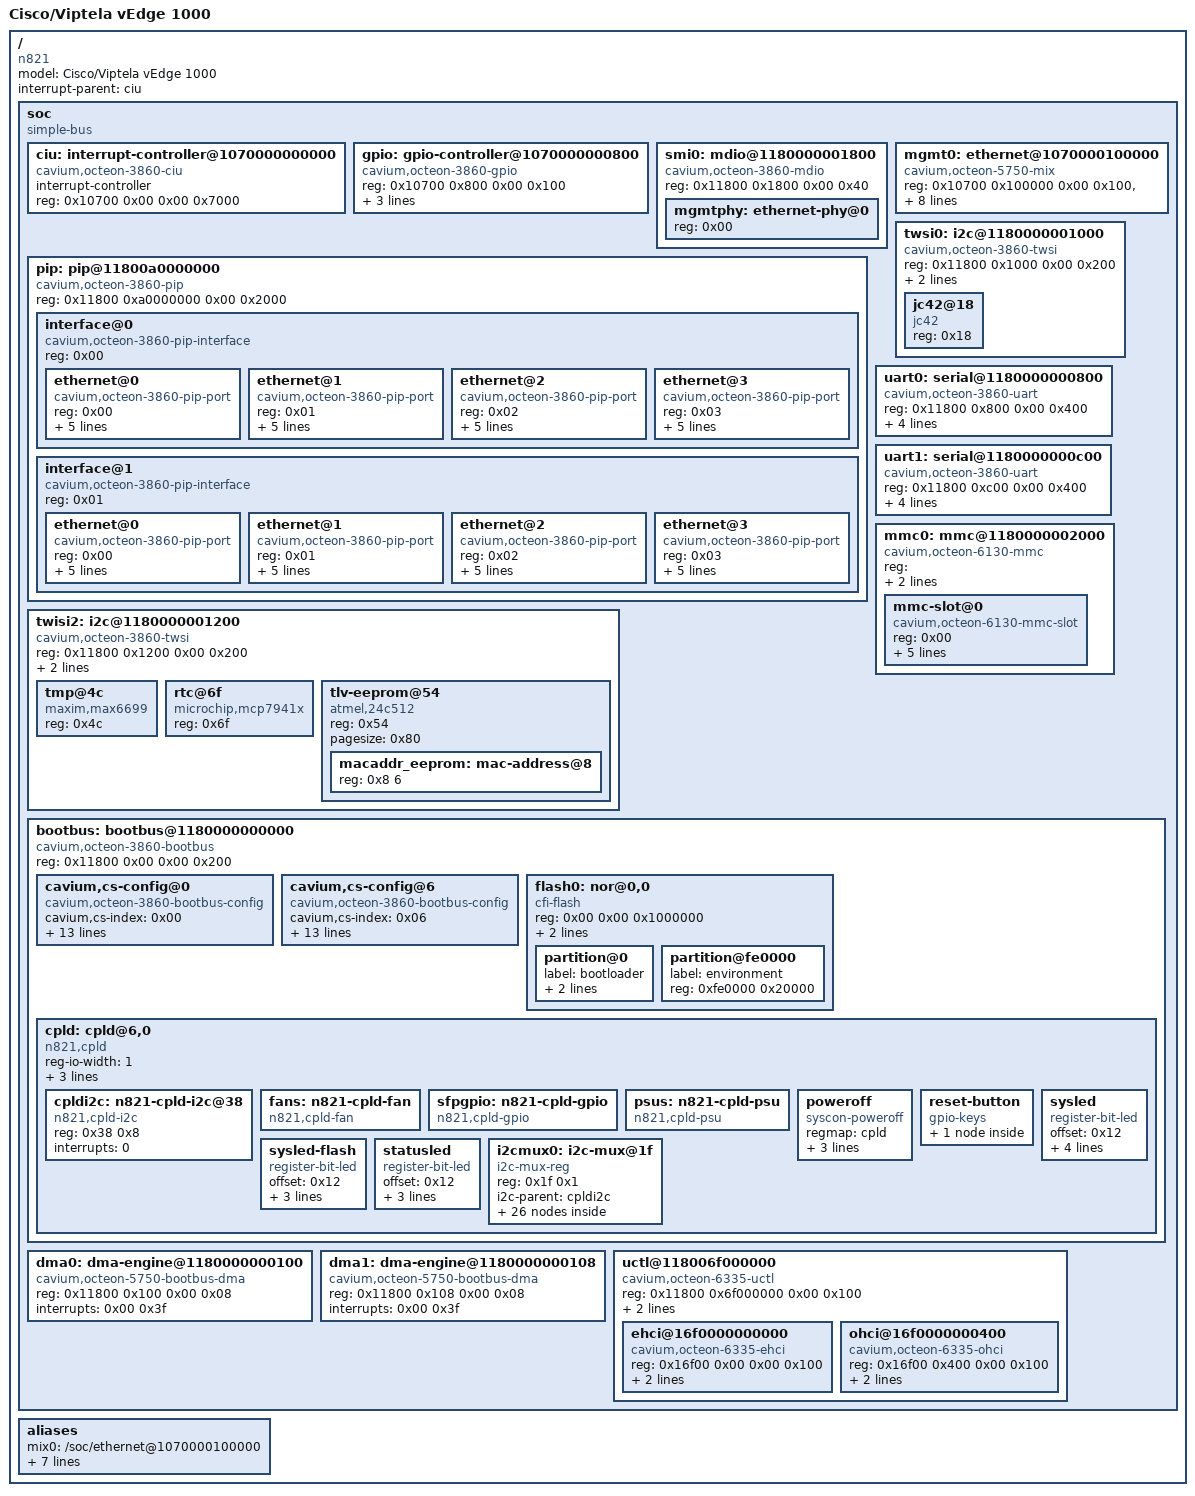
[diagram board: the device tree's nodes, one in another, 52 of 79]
/dts-v1/;

#include <dt-bindings/gpio/gpio.h>
#include <dt-bindings/input/input.h>
#include <dt-bindings/interrupt-controller/irq.h>

/ {
        model = "Cisco/Viptela vEdge 1000";
        compatible = "n821";
        #address-cells = <2>;
        #size-cells = <2>;
        interrupt-parent = <&ciu>;

        soc {
                compatible = "simple-bus";
                #address-cells = <2>;
                #size-cells = <2>;
                ranges; /* Direct mapping */

                ciu: interrupt-controller@1070000000000 {
                        compatible = "cavium,octeon-3860-ciu";
                        interrupt-controller;
                        #interrupt-cells = <2>;
                        reg = <0x10700 0x00 0x00 0x7000>;
                };

                gpio: gpio-controller@1070000000800 {
                        #gpio-cells = <2>;
                        compatible = "cavium,octeon-3860-gpio";
                        reg = <0x10700 0x800 0x00 0x100>;
                        gpio-controller;
                        interrupt-controller;
                        #interrupt-cells = <2>;
                        interrupts = <0x00 0x10>;
                };

                smi0: mdio@1180000001800 {
                        compatible = "cavium,octeon-3860-mdio";
                        #address-cells = <1>;
                        #size-cells = <0>;
                        reg = <0x11800 0x1800 0x00 0x40>;

                        mgmtphy: ethernet-phy@0 {
                                reg = <0x00>;
                        };
                };

                mgmt0: ethernet@1070000100000 {
                        compatible = "cavium,octeon-5750-mix";
                        reg = <0x10700 0x100000 0x00 0x100>,
                              <0x11800 0xe0000000 0x00 0x300>,
                              <0x11800 0xe0000400 0x00 0x400>,
                              <0x11800 0xe0002000 0x00 0x08>;
                        cell-index = <0x00>;
                        interrupts = <0x00 0x3e 0x01 0x2e>;
                        nvmem-cells = <&macaddr_eeprom>;
                        nvmem-cell-names = "mac-address";
                        phy-handle = <&mgmtphy>;
                };

                pip: pip@11800a0000000 {
                        compatible = "cavium,octeon-3860-pip";
                        #address-cells = <1>;
                        #size-cells = <0>;
                        reg = <0x11800 0xa0000000 0x00 0x2000>;

                        interface@0 {
                                compatible = "cavium,octeon-3860-pip-interface";
                                #address-cells = <1>;
                                #size-cells = <0>;
                                reg = <0x00>;

                                ethernet@0 {
                                        compatible = "cavium,octeon-3860-pip-port";
                                        reg = <0x00>;
                                        nvmem-cells = <&macaddr_eeprom>;
                                        nvmem-cell-names = "mac-address";
                                        mac-address-increment = <(3)>;
                                        label = "lan2";
                                        phy-handle = <&ge0_2_phy>;
                                };

                                ethernet@1 {
                                        compatible = "cavium,octeon-3860-pip-port";
                                        reg = <0x01>;
                                        nvmem-cells = <&macaddr_eeprom>;
                                        nvmem-cell-names = "mac-address";
                                        mac-address-increment = <(4)>;
                                        label = "lan3";
                                        phy-handle = <&ge0_3_phy>;
                                };

                                ethernet@2 {
                                        compatible = "cavium,octeon-3860-pip-port";
                                        reg = <0x02>;
                                        nvmem-cells = <&macaddr_eeprom>;
                                        nvmem-cell-names = "mac-address";
                                        mac-address-increment = <(1)>;
                                        label = "lan0";
                                        cavium,sgmii-mac-1000x-mode;
                                };

                                ethernet@3 {
                                        compatible = "cavium,octeon-3860-pip-port";
                                        reg = <0x03>;
                                        nvmem-cells = <&macaddr_eeprom>;
                                        nvmem-cell-names = "mac-address";
                                        mac-address-increment = <(2)>;
                                        label = "lan1";
                                        cavium,sgmii-mac-1000x-mode;
                                };
                        };

                        interface@1 {
                                compatible = "cavium,octeon-3860-pip-interface";
                                #address-cells = <1>;
                                #size-cells = <0>;
                                reg = <0x01>;

                                ethernet@0 {
                                        compatible = "cavium,octeon-3860-pip-port";
                                        reg = <0x00>;
                                        nvmem-cells = <&macaddr_eeprom>;
                                        nvmem-cell-names = "mac-address";
                                        mac-address-increment = <(7)>;
                                        label = "lan6";
                                        phy-handle = <&ge0_6_phy>;
                                };

                                ethernet@1 {
                                        compatible = "cavium,octeon-3860-pip-port";
                                        reg = <0x01>;
                                        nvmem-cells = <&macaddr_eeprom>;
                                        nvmem-cell-names = "mac-address";
                                        mac-address-increment = <(8)>;
                                        label = "lan7";
                                        phy-handle = <&ge0_7_phy>;
                                };

                                ethernet@2 {
                                        compatible = "cavium,octeon-3860-pip-port";
                                        reg = <0x02>;
                                        nvmem-cells = <&macaddr_eeprom>;
                                        nvmem-cell-names = "mac-address";
                                        mac-address-increment = <(5)>;
                                        label = "lan4";
                                        phy-handle = <&ge0_4_phy>;
                                };

                                ethernet@3 {
                                        compatible = "cavium,octeon-3860-pip-port";
                                        reg = <0x03>;
                                        nvmem-cells = <&macaddr_eeprom>;
                                        nvmem-cell-names = "mac-address";
                                        mac-address-increment = <(6)>;
                                        label = "lan5";
                                        phy-handle = <&ge0_5_phy>;
                                };
                        };
                };

                twsi0: i2c@1180000001000 {
                        #address-cells = <1>;
                        #size-cells = <0>;
                        compatible = "cavium,octeon-3860-twsi";
                        reg = <0x11800 0x1000 0x00 0x200>;
                        interrupts = <0x00 0x2d>;
                        clock-frequency = <400000>;

                        jc42@18 {
                                compatible = "jc42";
                                reg = <0x18>;
                        };
                };

                twisi2: i2c@1180000001200 {
                        #address-cells = <1>;
                        #size-cells = <0>;
                        compatible = "cavium,octeon-3860-twsi";
                        reg = <0x11800 0x1200 0x00 0x200>;
                        interrupts = <0x00 0x3b>;
                        clock-frequency = <400000>;

                        tmp@4c {
                                compatible = "maxim,max6699";
                                reg = <0x4c>;
                        };

                        rtc@6f {
                                compatible = "microchip,mcp7941x";
                                reg = <0x6f>;
                        };

                        tlv-eeprom@54 {
                                compatible = "atmel,24c512";
                                reg = <0x54>;
                                pagesize = <0x80>;
                                #address-cells = <1>;
                                #size-cells = <1>;

                                macaddr_eeprom: mac-address@8 {
                                        reg = <0x8 6>;
                                };
                        };
                };

                uart0: serial@1180000000800 {
                        compatible = "cavium,octeon-3860-uart", "ns16550";
                        reg = <0x11800 0x800 0x00 0x400>;
                        reg-shift = <0x03>;
                        interrupts = <0x00 0x22>;
                        clock-frequency = <600000000>;
                        current-speed = <115200>;
                };

                uart1: serial@1180000000c00 {
                        compatible = "cavium,octeon-3860-uart", "ns16550";
                        reg = <0x11800 0xc00 0x00 0x400>;
                        reg-shift = <0x03>;
                        interrupts = <0x00 0x23>;
                        clock-frequency = <600000000>;
                        current-speed = <115200>;
                };

                mmc0: mmc@1180000002000 {
                        compatible = "cavium,octeon-6130-mmc";
                        reg = <0x11800 0x2000 0x00 0x100 0x11800 0x168 0x00 0x20>;
                        #address-cells = <1>;
                        #size-cells = <0>;
                        interrupts = <0x01 0x13 0x00 0x3f>;

                        mmc-slot@0 {
                                compatible = "cavium,octeon-6130-mmc-slot";
                                reg = <0x00>;
                                voltage-ranges = <0xce4 0xce4>;
                                max-frequency = <0x3197500>;
                                wp-gpios = <&gpio 0x02 0x00>;
                                cd-gpios = <&gpio 0x03 0x01>;
                                cavium,bus-max-width = <0x04>;
                        };
                };

                bootbus: bootbus@1180000000000 {
                        compatible = "cavium,octeon-3860-bootbus";
                        reg = <0x11800 0x00 0x00 0x200>;
                        #address-cells = <2>;
                        #size-cells = <1>;
                        ranges = <0 0 0x00 0x1ec00000 0x1400000>,
                                 <1 0 0x10000 0x20000000 0x00>,
                                 <2 0 0x10000 0x30000000 0x00>,
                                 <3 0 0x10000 0x40000000 0x00>,
                                 <4 0 0x10000 0x50000000 0x00>,
                                 <5 0 0x10000 0x60000000 0x00>,
                                 <6 0 0x00 0x1e000000 0x10000>,
                                 <7 0 0x10000 0x80000000 0x00>;

                        cavium,cs-config@0 {
                                compatible = "cavium,octeon-3860-bootbus-config";
                                cavium,cs-index = <0x00>;
                                cavium,t-adr = <0x0a>;
                                cavium,t-ce = <0x32>;
                                cavium,t-oe = <0x32>;
                                cavium,t-we = <0x23>;
                                cavium,t-rd-hld = <0x19>;
                                cavium,t-wr-hld = <0x23>;
                                cavium,t-pause = <0x00>;
                                cavium,t-wait = <0x12c>;
                                cavium,t-page = <0x19>;
                                cavium,t-rd-dly = <0x00>;
                                cavium,t-ale = <0x03>;
                                cavium,pages = <0x00>;
                                cavium,bus-width = <0x10>;
                        };

                        cavium,cs-config@6 {
                                compatible = "cavium,octeon-3860-bootbus-config";
                                cavium,cs-index = <0x06>;
                                cavium,t-adr = <0x0a>;
                                cavium,t-ce = <0x0a>;
                                cavium,t-oe = <0xa0>;
                                cavium,t-we = <0x64>;
                                cavium,t-rd-hld = <0x00>;
                                cavium,t-wr-hld = <0x00>;
                                cavium,t-pause = <0x32>;
                                cavium,t-wait = <0x12c>;
                                cavium,t-page = <0x12c>;
                                cavium,t-rd-dly = <0x0a>;
                                cavium,t-ale = <0x3f>;
                                cavium,pages = <0x00>;
                                cavium,bus-width = <0x08>;
                        };

                        flash0: nor@0,0 {
                                compatible = "cfi-flash";
                                reg = <0x00 0x00 0x1000000>;
                                /* not sure about these values */
                                bank-width = <2>;
                                device-width = <1>;

                                #address-cells = <1>;
                                #size-cells = <1>;

                                partition@0 {
                                        label = "bootloader";
                                        reg = <0x00 0x200000>;
                                        read-only;
                                };

                                partition@fe0000 {
                                        label = "environment";
                                        reg = <0xfe0000 0x20000>;
                                };
                        };

                        cpld: cpld@6,0 {
                                compatible = "n821,cpld", "syscon", "simple-mfd";
                                #address-cells = <1>;
                                #size-cells = <1>;
                                reg-io-width = <1>; // Syscon uses 4-byte accesses by default

                                reg = <0x06 0x00 0x28>;     // This is the regmap to be defined for syscon devices..
                                ranges = <0 0x06 0x0 0x50>; // .. and this is the addresses to map general subdevices on

                                interrupt-controller;
                                #interrupt-cells = <1>;
                                interrupts-extended = <&gpio 1 IRQ_TYPE_LEVEL_LOW>;

                                cpldi2c: n821-cpld-i2c@38 {
                                        compatible = "n821,cpld-i2c";
                                        reg = <0x38 0x8>;
                                        interrupts = <0>; // TODO: Verify correct IRQ
                                };

                                fans: n821-cpld-fan {
                                        compatible = "n821,cpld-fan";
                                };

                                sfpgpio: n821-cpld-gpio {
                                        compatible = "n821,cpld-gpio";
                                        #gpio-cells = <2>;
                                };

                                psus: n821-cpld-psu {
                                        compatible = "n821,cpld-psu";
                                };

                                poweroff {
                                        compatible = "syscon-poweroff";
                                        regmap = <&cpld>;
                                        offset = <0x5>;
                                        value = <0>;
                                        mask = <0xff>;
                                };

                                reset-button {
                                        compatible = "gpio-keys";
                                        reset {
                                                  label = "reset";
                                                  interrupts = <1>;
                                                  linux,code = <KEY_RESTART>;
                                                  debounce-interval = <60>;
                                        };
                                };

                                sysled {
                                        compatible = "register-bit-led";
                                        offset = <0x12>;
                                        mask = <0x1>;
                                        label = "green:activity";
                                        linux,default-trigger = "heartbeat";
                                        default-state = "on";
                                };
                                sysled-flash {
                                        compatible = "register-bit-led";
                                        offset = <0x12>;
                                        mask = <0x2>;
                                        label = "green:activity-flash";
                                        default-state = "off";
                                };
                                statusled {
                                        compatible = "register-bit-led";
                                        offset = <0x12>;
                                        mask = <0x10>;
                                        label = "green:status";
                                        default-state = "on";
                                };

                                i2cmux0: i2c-mux@1f {
                                        compatible = "i2c-mux-reg";
                                        reg = <0x1f 0x1>;
                                        #address-cells = <1>;
                                        #size-cells = <0>;
                                        i2c-parent = <&cpldi2c>;

                                        ge0_6_i2c: i2c@0 {
                                                reg = <0x00>;
                                                i2c-name = "ge0_6";
                                                #address-cells = <1>;
                                                #size-cells = <0>;
#ifndef PHYLINK_SFP
                                                ge0_6_mdio: mdio@56 {
                                                        compatible = "mdio-i2c-gen";
                                                        reg = <0x56>;
                                                        #address-cells = <1>;
                                                        #size-cells = <0>;
                                                        ge0_6_phy: phy@16 {
                                                                reg = <0x16>;
                                                        };
                                                };
#endif
                                        };

                                        ge0_7_i2c: i2c@1 {
                                                reg = <0x01>;
                                                i2c-name = "ge0_7";
                                                #address-cells = <1>;
                                                #size-cells = <0>;
#ifndef PHYLINK_SFP
                                                ge0_7_mdio: mdio@56 {
                                                        compatible = "mdio-i2c-gen";
                                                        reg = <0x56>;
                                                        #address-cells = <1>;
                                                        #size-cells = <0>;
                                                        ge0_7_phy: phy@16 {
                                                                reg = <0x16>;
                                                        };
                                                };
#endif
                                        };

                                        ge0_4_i2c: i2c@2 {
                                                reg = <0x02>;
                                                i2c-name = "ge0_4";
                                                #address-cells = <1>;
                                                #size-cells = <0>;
#ifndef PHYLINK_SFP
                                                ge0_4_mdio: mdio@56 {
                                                        compatible = "mdio-i2c-gen";
                                                        reg = <0x56>;
                                                        #address-cells = <1>;
                                                        #size-cells = <0>;
                                                        ge0_4_phy: phy@16 {
                                                                reg = <0x16>;
                                                        };
                                                };
#endif
                                        };

                                        ge0_5_i2c: i2c@3 {
                                                reg = <0x03>;
                                                i2c-name = "ge0_5";
                                                #address-cells = <1>;
                                                #size-cells = <0>;
#ifndef PHYLINK_SFP
                                                ge0_5_mdio: mdio@56 {
                                                        compatible = "mdio-i2c-gen";
                                                        reg = <0x56>;
                                                        #address-cells = <1>;
                                                        #size-cells = <0>;
                                                        ge0_5_phy: phy@16 {
                                                                reg = <0x16>;
                                                        };
                                                };
#endif
                                        };

                                        ge0_2_i2c: i2c@4 {
                                                reg = <0x04>;
                                                i2c-name = "ge0_2";
                                                #address-cells = <1>;
                                                #size-cells = <0>;
#ifndef PHYLINK_SFP
                                                ge0_2_mdio: mdio@56 {
                                                        compatible = "mdio-i2c-gen";
                                                        reg = <0x56>;
                                                        #address-cells = <1>;
                                                        #size-cells = <0>;
                                                        ge0_2_phy: phy@16 {
                                                                reg = <0x16>;
                                                        };
                                                };
#endif
                                        };

                                        ge0_3_i2c: i2c@5 {
                                                reg = <0x05>;
                                                i2c-name = "ge0_3";
                                                #address-cells = <1>;
                                                #size-cells = <0>;
#ifndef PHYLINK_SFP
                                                ge0_3_mdio: mdio@56 {
                                                        compatible = "mdio-i2c-gen";
                                                        reg = <0x56>;
                                                        #address-cells = <1>;
                                                        #size-cells = <0>;
                                                        ge0_3_phy: phy@16 {
                                                                reg = <0x16>;
                                                        };
                                                };
#endif
                                        };

                                        ge0_0_i2c: i2c@6 {
                                                reg = <0x06>;
                                                i2c-name = "ge0_0";
                                                #address-cells = <1>;
                                                #size-cells = <0>;
#ifndef PHYLINK_SFP
                                                ge0_0_mdio: mdio@56 {
                                                        compatible = "mdio-i2c-gen";
                                                        reg = <0x56>;
                                                        #address-cells = <1>;
                                                        #size-cells = <0>;
                                                        ge0_0_phy: phy@16 {
                                                                reg = <0x16>;
                                                        };
                                                };
#endif
                                        };

                                        ge0_1_i2c: i2c@7 {
                                                reg = <0x07>;
                                                i2c-name = "ge0_1";
                                                #address-cells = <1>;
                                                #size-cells = <0>;
#ifndef PHYLINK_SFP
                                                ge0_1_mdio: mdio@56 {
                                                        compatible = "mdio-i2c-gen";
                                                        reg = <0x56>;
                                                        #address-cells = <1>;
                                                        #size-cells = <0>;
                                                        ge0_1_phy: phy@16 {
                                                                reg = <0x16>;
                                                        };
                                                };
#endif
                                        };

                                        i2c@10 {
                                                reg = <0x10>;
                                                i2c-name = "temp";
                                                #address-cells = <1>;
                                                #size-cells = <0>;

                                                temp@4c {
                                                        compatible = "max6657";
                                                        reg = <0x4c>;
                                                };
                                        };
                                };
                        };
                };

                dma0: dma-engine@1180000000100 {
                        compatible = "cavium,octeon-5750-bootbus-dma";
                        reg = <0x11800 0x100 0x00 0x08>;
                        interrupts = <0x00 0x3f>;
                };

                dma1: dma-engine@1180000000108 {
                        compatible = "cavium,octeon-5750-bootbus-dma";
                        reg = <0x11800 0x108 0x00 0x08>;
                        interrupts = <0x00 0x3f>;
                };

                uctl@118006f000000 {
                        compatible = "cavium,octeon-6335-uctl";
                        reg = <0x11800 0x6f000000 0x00 0x100>;
                        ranges;
                        #address-cells = <2>;
                        #size-cells = <2>;
                        refclk-frequency = <0xb71b00>;
                        refclk-type = "crystal";

                        ehci@16f0000000000 {
                                compatible = "cavium,octeon-6335-ehci", "usb-ehci";
                                reg = <0x16f00 0x00 0x00 0x100>;
                                interrupts = <0x00 0x38>;
                                big-endian-regs;
                        };

                        ohci@16f0000000400 {
                                compatible = "cavium,octeon-6335-ohci", "usb-ohci";
                                reg = <0x16f00 0x400 0x00 0x100>;
                                interrupts = <0x00 0x38>;
                                big-endian-regs;
                        };
                };
        };

        aliases {
                mix0 = "/soc/ethernet@1070000100000";
                pip = "/soc/pip@11800a0000000";
                twsi0 = "/soc/i2c@1180000001000";
                twsi1 = "/soc/i2c@1180000001200";
                uart0 = "/soc/serial@1180000000800";
                flash0 = "/soc/bootbus@1180000000000/nor@0,0";
                emmc = "/soc/mmc@1180000002000";
                cpld = "/soc/bootbus@1180000000000/cpld@6,0";
        };
};

